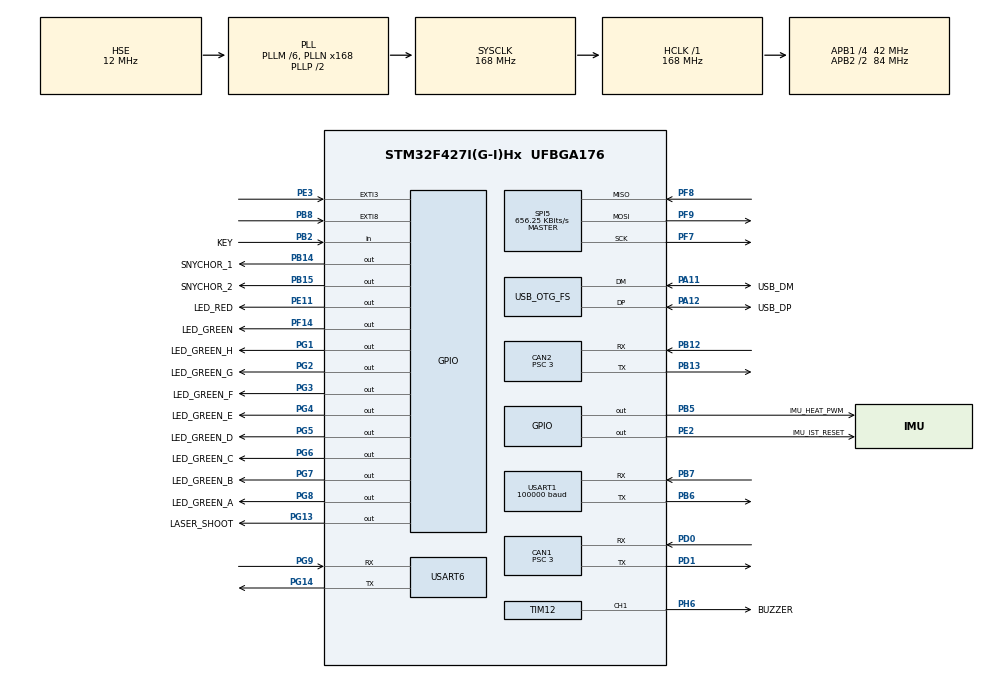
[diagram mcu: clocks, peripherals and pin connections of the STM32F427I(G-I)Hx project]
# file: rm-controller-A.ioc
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CAN1.BS1=CAN_BS1_10TQ
CAN1.BS2=CAN_BS2_3TQ
CAN1.CalculateBaudRate=1000000
CAN1.CalculateTimeBit=1000
CAN1.CalculateTimeQuantum=71.42857142857143
CAN1.Prescaler=3
CAN2.BS1=CAN_BS1_10TQ
CAN2.BS2=CAN_BS2_3TQ
CAN2.CalculateBaudRate=1000000
CAN2.CalculateTimeBit=1000
CAN2.CalculateTimeQuantum=71.42857142857143
CAN2.Prescaler=3
Dma.Request0=USART6_RX
Dma.Request1=USART6_TX
Dma.Request2=USART1_RX
Dma.USART1_RX.2.Direction=DMA_PERIPH_TO_MEMORY
Dma.USART1_RX.2.FIFOMode=DMA_FIFOMODE_DISABLE
Dma.USART1_RX.2.Instance=DMA2_Stream2
Dma.USART1_RX.2.MemDataAlignment=DMA_MDATAALIGN_BYTE
Dma.USART1_RX.2.MemInc=DMA_MINC_ENABLE
Dma.USART1_RX.2.Mode=DMA_CIRCULAR
Dma.USART1_RX.2.PeriphDataAlignment=DMA_PDATAALIGN_BYTE
Dma.USART1_RX.2.PeriphInc=DMA_PINC_DISABLE
Dma.USART1_RX.2.Priority=DMA_PRIORITY_VERY_HIGH
Dma.USART6_RX.0.Direction=DMA_PERIPH_TO_MEMORY
Dma.USART6_RX.0.FIFOMode=DMA_FIFOMODE_DISABLE
Dma.USART6_RX.0.Instance=DMA2_Stream1
Dma.USART6_RX.0.MemDataAlignment=DMA_MDATAALIGN_BYTE
Dma.USART6_RX.0.MemInc=DMA_MINC_ENABLE
Dma.USART6_RX.0.Mode=DMA_CIRCULAR
Dma.USART6_RX.0.PeriphDataAlignment=DMA_PDATAALIGN_BYTE
Dma.USART6_RX.0.PeriphInc=DMA_PINC_DISABLE
Dma.USART6_RX.0.Priority=DMA_PRIORITY_LOW
Dma.USART6_TX.1.Direction=DMA_MEMORY_TO_PERIPH
Dma.USART6_TX.1.FIFOMode=DMA_FIFOMODE_DISABLE
Dma.USART6_TX.1.Instance=DMA2_Stream6
Dma.USART6_TX.1.MemDataAlignment=DMA_MDATAALIGN_BYTE
Dma.USART6_TX.1.MemInc=DMA_MINC_ENABLE
Dma.USART6_TX.1.Mode=DMA_CIRCULAR
Dma.USART6_TX.1.PeriphDataAlignment=DMA_PDATAALIGN_BYTE
Dma.USART6_TX.1.PeriphInc=DMA_PINC_DISABLE
Dma.USART6_TX.1.Priority=DMA_PRIORITY_LOW
FREERTOS.Tasks01=default_task,24,300,defaultTask,As weak,NULL,Dynamic,NULL,NULL
FREERTOS.configENABLE_FPU=1
FREERTOS.configMINIMAL_STACK_SIZE=300
FREERTOS.configTOTAL_HEAP_SIZE=60000
FREERTOS.configUSE_POSIX_ERRNO=1
Mcu.Family=STM32F4
Mcu.Name=STM32F427I(G-I)Hx
Mcu.Package=UFBGA176
NVIC.CAN1_RX0_IRQn=true\:5\:0\:false\:false\:true\:true\:true\:true\:true
NVIC.CAN2_RX0_IRQn=true\:5\:0\:false\:false\:true\:true\:true\:true\:true
NVIC.DMA2_Stream1_IRQn=true\:5\:0\:false\:false\:true\:true\:false\:true\:true
NVIC.DMA2_Stream2_IRQn=true\:5\:0\:false\:false\:true\:true\:false\:true\:true
NVIC.DMA2_Stream6_IRQn=true\:5\:0\:false\:false\:true\:true\:false\:true\:true
NVIC.OTG_FS_IRQn=true\:10\:0\:true\:false\:true\:true\:false\:true\:true
NVIC.PriorityGroup=NVIC_PRIORITYGROUP_4
NVIC.TIM1_UP_TIM10_IRQn=true\:15\:0\:true\:false\:true\:false\:false\:true\:true
NVIC.TimeBase=TIM1_UP_TIM10_IRQn
NVIC.TimeBaseIP=TIM1
NVIC.USART6_IRQn=true\:5\:0\:false\:false\:true\:true\:true\:true\:true
PA10.GPIO_Label=USB_ID
PA10.Signal=USB_OTG_FS_ID
PA11.GPIO_Label=USB_DM
PA11.Mode=Device_Only
PA11.Signal=USB_OTG_FS_DM
PA12.GPIO_Label=USB_DP
PA12.Mode=Device_Only
PA12.Signal=USB_OTG_FS_DP
PA13.Mode=Serial_Wire
PA13.Signal=SYS_JTMS-SWDIO
PA14.Mode=Serial_Wire
PA14.Signal=SYS_JTCK-SWCLK
PB12.Mode=CAN_Activate
PB12.Signal=CAN2_RX
PB13.Mode=CAN_Activate
PB13.Signal=CAN2_TX
PB14.GPIO_Label=SNYCHOR_1
PB14.Signal=GPIO_Output
PB15.GPIO_Label=SNYCHOR_2
PB15.Signal=GPIO_Output
PB2/BOOT1.GPIO_Label=KEY
PB2/BOOT1.Signal=GPIO_Input
PB5.GPIO_Label=IMU_HEAT_PWM
PB5.Signal=GPIO_Output
PB6.Mode=Asynchronous
PB6.Signal=USART1_TX
PB7.Mode=Asynchronous
PB7.Signal=USART1_RX
PB8.GPIO_ModeDefaultEXTI=GPIO_MODE_IT_FALLING
PB8.GPIO_PuPd=GPIO_PULLUP
PB8.Signal=GPXTI8
PD0.Mode=CAN_Activate
PD0.Signal=CAN1_RX
PD1.Mode=CAN_Activate
PD1.Signal=CAN1_TX
PD5.GPIO_Label=BL_TX
PD5.Signal=USART2_TX
PD6.GPIO_Label=BL_RX
PD6.Signal=USART2_RX
PD8.Signal=USART3_TX
PD9.Signal=USART3_RX
PE0.Signal=UART8_RX
PE1.Signal=UART8_TX
PE11.GPIO_Label=LED_RED
PE11.PinState=GPIO_PIN_SET
PE11.Signal=GPIO_Output
PE2.GPIO_Label=IMU_IST_RESET
PE2.Signal=GPIO_Output
PE3.GPIO_ModeDefaultEXTI=GPIO_MODE_IT_FALLING
PE3.GPIO_PuPd=GPIO_PULLUP
PE3.Signal=GPXTI3
PE7.Signal=UART7_RX
PE8.Signal=UART7_TX
PF14.GPIO_Label=LED_GREEN
PF14.Signal=GPIO_Output
PF6.Signal=SPI5_NSS
PF7.Mode=Full_Duplex_Master
PF7.Signal=SPI5_SCK
PF8.Mode=Full_Duplex_Master
PF8.Signal=SPI5_MISO
PF9.Mode=Full_Duplex_Master
PF9.Signal=SPI5_MOSI
PG1.GPIO_Label=LED_GREEN_H
PG1.PinState=GPIO_PIN_SET
PG1.Signal=GPIO_Output
PG13.GPIO_Label=LASER_SHOOT
PG13.Signal=GPIO_Output
PG14.Mode=Asynchronous
PG14.Signal=USART6_TX
PG2.GPIO_Label=LED_GREEN_G
PG2.Signal=GPIO_Output
PG3.GPIO_Label=LED_GREEN_F
PG3.PinState=GPIO_PIN_SET
PG3.Signal=GPIO_Output
PG4.GPIO_Label=LED_GREEN_E
PG4.PinState=GPIO_PIN_SET
PG4.Signal=GPIO_Output
PG5.GPIO_Label=LED_GREEN_D
PG5.PinState=GPIO_PIN_SET
PG5.Signal=GPIO_Output
PG6.GPIO_Label=LED_GREEN_C
PG6.PinState=GPIO_PIN_SET
PG6.Signal=GPIO_Output
PG7.GPIO_Label=LED_GREEN_B
PG7.PinState=GPIO_PIN_SET
PG7.Signal=GPIO_Output
PG8.GPIO_Label=LED_GREEN_A
PG8.PinState=GPIO_PIN_SET
PG8.Signal=GPIO_Output
PG9.Mode=Asynchronous
PG9.Signal=USART6_RX
PH0/OSC_IN.Mode=HSE-External-Oscillator
PH0/OSC_IN.Signal=RCC_OSC_IN
PH1/OSC_OUT.Mode=HSE-External-Oscillator
PH1/OSC_OUT.Signal=RCC_OSC_OUT
PH6.GPIO_Label=BUZZER
PH6.Signal=S_TIM12_CH1
ProjectManager.HeapSize=0x1000
ProjectManager.StackSize=0x1000
ProjectManager.TargetToolchain=Makefile
RCC.48MHZClocksFreq_Value=48000000
RCC.AHBFreq_Value=168000000
RCC.APB1CLKDivider=RCC_HCLK_DIV4
RCC.APB1Freq_Value=42000000
RCC.APB1TimFreq_Value=84000000
RCC.APB2CLKDivider=RCC_HCLK_DIV2
RCC.APB2Freq_Value=84000000
RCC.APB2TimFreq_Value=168000000
RCC.CortexFreq_Value=168000000
RCC.HCLKFreq_Value=168000000
RCC.HSE_VALUE=12000000
RCC.HSI_VALUE=16000000
RCC.LSE_VALUE=32768
RCC.PLLM=6
RCC.PLLMUL=RCC_PLL_MUL9
RCC.PLLN=168
RCC.PLLQ=7
RCC.PRESCALERUSB=RCC_USBCLKSOURCE_PLL_DIV1_5
RCC.SYSCLKFreq_VALUE=168000000
RCC.SYSCLKSource=RCC_SYSCLKSOURCE_PLLCLK
RCC.SYSCLKSourceVirtual=RCC_SYSCLKSOURCE_PLLCLK
RCC.USBFreq_Value=48000000
RCC.VCOOutputFreq_Value=336000000
SH.S_TIM12_CH1.0=TIM12_CH1,PWM Generation1 CH1
SPI5.BaudRatePrescaler=SPI_BAUDRATEPRESCALER_128
SPI5.CalculateBaudRate=656.25 KBits/s
SPI5.Direction=SPI_DIRECTION_2LINES
SPI5.Mode=SPI_MODE_MASTER
SPI5.VirtualType=VM_MASTER
TIM12.Channel-PWM\ Generation1\ CH1=TIM_CHANNEL_1
TIM12.OCMode_PWM-PWM\ Generation1\ CH1=TIM_OCMODE_PWM1
USART1.BaudRate=100000
USART1.Mode=MODE_RX
USART1.Parity=PARITY_EVEN
USART1.VirtualMode=VM_ASYNC
USART6.VirtualMode=VM_ASYNC
USB_DEVICE.CLASS_NAME_FS=CDC
USB_DEVICE.MANUFACTURER_STRING-CDC_FS=Manufacturer String
USB_DEVICE.PRODUCT_STRING_CDC_FS=Product String
USB_DEVICE.USBD_DEBUG_LEVEL-CDC_FS=3
USB_DEVICE.VirtualMode-CDC_FS=Cdc
USB_DEVICE.VirtualModeFS=Cdc_FS
USB_OTG_FS.VirtualMode=Device_Only
VP_FREERTOS_VS_CMSIS_V2.Mode=CMSIS_V2
VP_SYS_VS_tim1.Mode=TIM1
VP_USB_DEVICE_VS_USB_DEVICE_CDC_FS.Mode=CDC_FS
board=Robomaster-Development-A

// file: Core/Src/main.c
/* USER CODE BEGIN Header */
/**
  ******************************************************************************
  * @file           : main.c
  * @brief          : Main program body
  ******************************************************************************
  * @attention
  *
  * Copyright (c) 2022 STMicroelectronics.
  * All rights reserved.
  *
  * This software is licensed under terms that can be found in the LICENSE file
  * in the root directory of this software component.
  * If no LICENSE file comes with this software, it is provided AS-IS.
  *
  ******************************************************************************
  */
/* USER CODE END Header */
#include "main.h"
#include "cmsis_os.h"
#include "can.h"
#include "dma.h"
#include "spi.h"
#include "tim.h"
#include "usart.h"
#include "usb_device.h"
#include "gpio.h"

/* USER CODE BEGIN Includes */
#include "init.h"

/* USER CODE END Includes */

/* USER CODE BEGIN PV */
extern uint8_t UART_RxBuffer[2048];
/* USER CODE END PV */

void SystemClock_Config(void);
void MX_FREERTOS_Init(void);
/* USER CODE BEGIN PFP */
// #define BUFSIZE 4096
// char buffer[BUFSIZE];
// extern struct netif gnetif;
// UART_HandleTypeDef *printf_uart = &huart6;
/* USER CODE END PFP */

/* USER CODE BEGIN 0 */

extern void initialise_monitor_handles(void);

/* USER CODE END 0 */

int main(void)
{
  /* USER CODE BEGIN 1 */
  // initialise_monitor_handles();
  // printf("hello world");
  /* USER CODE END 1 */

  /* MCU Configuration--------------------------------------------------------*/

  /* Reset of all peripherals, Initializes the Flash interface and the Systick. */
  HAL_Init();

  /* Configure the system clock */
  SystemClock_Config();

  /* Initialize all configured peripherals */
  MX_GPIO_Init();
  MX_DMA_Init();
  MX_CAN1_Init();
  MX_CAN2_Init();
  MX_SPI5_Init();
  MX_TIM12_Init();
  MX_USART6_UART_Init();
  MX_USART1_UART_Init();
  /* USER CODE BEGIN 2 */
  userCodeInit();

  /* USER CODE END 2 */

  /* Init scheduler */
  osKernelInitialize();  /* Call init function for freertos objects (in freertos.c) */
  MX_FREERTOS_Init();

  /* Start scheduler */
  osKernelStart();

  /* We should never get here as control is now taken by the scheduler */
  /* Infinite loop */
  while (1)
  {

    /* USER CODE BEGIN 3 */
    printf("help\n");
    // HAL_Delay(1000);
  }
  /* USER CODE END 3 */
}

void SystemClock_Config(void)
{
  RCC_OscInitTypeDef RCC_OscInitStruct = {0};
  RCC_ClkInitTypeDef RCC_ClkInitStruct = {0};

  /** Configure the main internal regulator output voltage
  */
  __HAL_RCC_PWR_CLK_ENABLE();
  __HAL_PWR_VOLTAGESCALING_CONFIG(PWR_REGULATOR_VOLTAGE_SCALE1);

  /** Initializes the RCC Oscillators according to the specified parameters
  * in the RCC_OscInitTypeDef structure.
  */
  RCC_OscInitStruct.OscillatorType = RCC_OSCILLATORTYPE_HSE;
  RCC_OscInitStruct.HSEState = RCC_HSE_ON;
  RCC_OscInitStruct.PLL.PLLState = RCC_PLL_ON;
  RCC_OscInitStruct.PLL.PLLSource = RCC_PLLSOURCE_HSE;
  RCC_OscInitStruct.PLL.PLLM = 6;
  RCC_OscInitStruct.PLL.PLLN = 168;
  RCC_OscInitStruct.PLL.PLLP = RCC_PLLP_DIV2;
  RCC_OscInitStruct.PLL.PLLQ = 7;
  if (HAL_RCC_OscConfig(&RCC_OscInitStruct) != HAL_OK)
  {
    Error_Handler();
  }

  /** Initializes the CPU, AHB and APB buses clocks
  */
  RCC_ClkInitStruct.ClockType = RCC_CLOCKTYPE_HCLK|RCC_CLOCKTYPE_SYSCLK
                              |RCC_CLOCKTYPE_PCLK1|RCC_CLOCKTYPE_PCLK2;
  RCC_ClkInitStruct.SYSCLKSource = RCC_SYSCLKSOURCE_PLLCLK;
  RCC_ClkInitStruct.AHBCLKDivider = RCC_SYSCLK_DIV1;
  RCC_ClkInitStruct.APB1CLKDivider = RCC_HCLK_DIV4;
  RCC_ClkInitStruct.APB2CLKDivider = RCC_HCLK_DIV2;

  if (HAL_RCC_ClockConfig(&RCC_ClkInitStruct, FLASH_LATENCY_5) != HAL_OK)
  {
    Error_Handler();
  }
}

void HAL_TIM_PeriodElapsedCallback(TIM_HandleTypeDef *htim)
{
  if (htim->Instance == TIM1) {
    HAL_IncTick();
  }
}

void Error_Handler(void)
{
  __disable_irq();
  while (1)
  {
  }
}

#ifdef  USE_FULL_ASSERT
/**
  * @brief  Reports the name of the source file and the source line number
  *         where the assert_param error has occurred.
  * @param  file: pointer to the source file name
  * @param  line: assert_param error line source number
  * @retval None
  */
void assert_failed(uint8_t *file, uint32_t line)
{
  /* USER CODE BEGIN 6 */
  /* User can add his own implementation to report the file name and line number, */
  printf("Wrong parameters value: file %s on line %d\r\n", file, line);
  /* USER CODE END 6 */
}
#endif /* USE_FULL_ASSERT */

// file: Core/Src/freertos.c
/* USER CODE BEGIN Header */
/**
  ******************************************************************************
  * File Name          : freertos.c
  * Description        : Code for freertos applications
  ******************************************************************************
  * @attention
  *
  * Copyright (c) 2022 STMicroelectronics.
  * All rights reserved.
  *
  * This software is licensed under terms that can be found in the LICENSE file
  * in the root directory of this software component.
  * If no LICENSE file comes with this software, it is provided AS-IS.
  *
  ******************************************************************************
  */
/* USER CODE END Header */

#include "FreeRTOS.h"
#include "task.h"
#include "main.h"
#include "cmsis_os.h"

/* Definitions for default_task */
osThreadId_t default_taskHandle;
const osThreadAttr_t default_task_attributes = {
  .name = "default_task",
  .stack_size = 300 * 4,
  .priority = (osPriority_t) osPriorityNormal,
};

void defaultTask(void *argument);

extern void MX_USB_DEVICE_Init(void);
void MX_FREERTOS_Init(void); /* (MISRA C 2004 rule 8.1) */

void MX_FREERTOS_Init(void) {

  /* Create the thread(s) */
  /* creation of default_task */
  default_taskHandle = osThreadNew(defaultTask, NULL, &default_task_attributes);

}

__weak void defaultTask(void *argument)
{
  /* init code for USB_DEVICE */
  MX_USB_DEVICE_Init();
  for(;;)
  {
    osDelay(1);
  }
}
